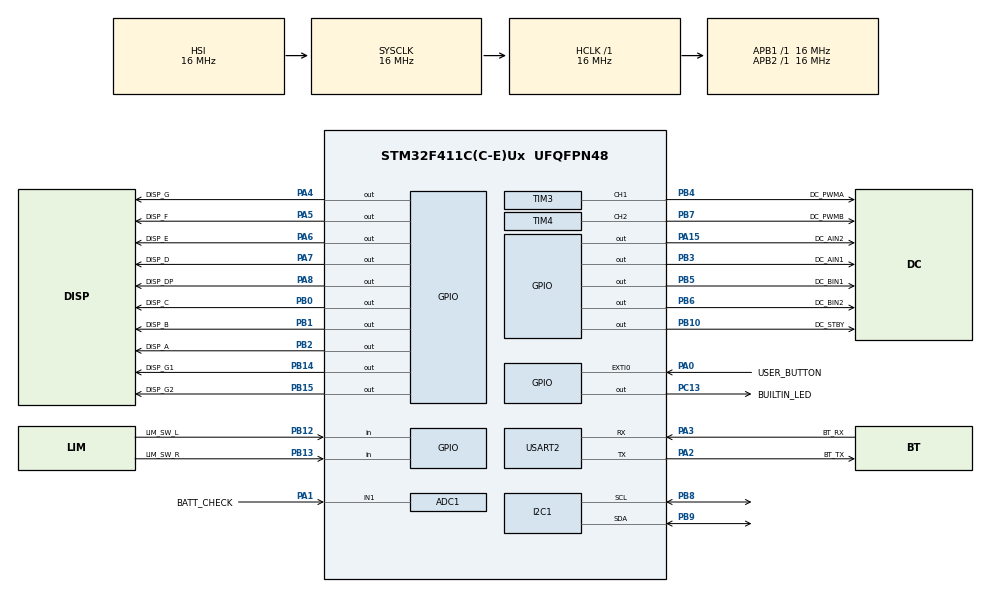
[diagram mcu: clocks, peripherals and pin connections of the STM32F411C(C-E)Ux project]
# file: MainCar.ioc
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ADC1.Channel-0\#ChannelRegularConversion=ADC_CHANNEL_1
ADC1.NbrOfConversionFlag=1
ADC1.Rank-0\#ChannelRegularConversion=1
ADC1.SamplingTime-0\#ChannelRegularConversion=ADC_SAMPLETIME_3CYCLES
ADC1.master=1
FREERTOS.Queues01=btTx,64,uint16_t,0,Dynamic,NULL,NULL;btRx,64,uint16_t,0,Dynamic,NULL,NULL
FREERTOS.Tasks01=defaultTask,24,128,startDefaultTask,Default,NULL,Dynamic,NULL,NULL;displayTask,9,1024,startDisplayTask,Default,NULL,Dynamic,NULL,NULL;driveTask,9,2048,startDriveTask,Default,NULL,Dynamic,NULL,NULL;btTask,8,2048,startBtTask,Default,NULL,Dynamic,NULL,NULL
Mcu.Family=STM32F4
Mcu.Name=STM32F411C(C-E)Ux
Mcu.Package=UFQFPN48
NVIC.PriorityGroup=NVIC_PRIORITYGROUP_4
PA0-WKUP.GPIO_Label=USER_BUTTON
PA0-WKUP.GPIO_PuPd=GPIO_PULLUP
PA0-WKUP.Signal=GPXTI0
PA1.GPIO_Label=BATT_CHECK
PA1.Signal=SharedAnalog_PA1
PA10.Signal=USART1_RX
PA15.GPIO_Label=DC_AIN2
PA15.Signal=GPIO_Output
PA2.GPIO_Label=BT_TX
PA2.Mode=Asynchronous
PA2.Signal=USART2_TX
PA3.GPIO_Label=BT_RX
PA3.Mode=Asynchronous
PA3.Signal=USART2_RX
PA4.GPIO_Label=DISP_G
PA4.Signal=GPIO_Output
PA5.GPIO_Label=DISP_F
PA5.Signal=GPIO_Output
PA6.GPIO_Label=DISP_E
PA6.Signal=GPIO_Output
PA7.GPIO_Label=DISP_D
PA7.Signal=GPIO_Output
PA8.GPIO_Label=DISP_DP
PA8.Signal=GPIO_Output
PA9.Signal=USART1_TX
PB0.GPIO_Label=DISP_C
PB0.Signal=GPIO_Output
PB1.GPIO_Label=DISP_B
PB1.Signal=GPIO_Output
PB10.GPIO_Label=DC_STBY
PB10.Signal=GPIO_Output
PB12.GPIO_Label=LIM_SW_L
PB12.GPIO_PuPd=GPIO_PULLUP
PB12.Signal=GPIO_Input
PB13.GPIO_Label=LIM_SW_R
PB13.GPIO_PuPd=GPIO_PULLUP
PB13.Signal=GPIO_Input
PB14.GPIO_Label=DISP_G1
PB14.Signal=GPIO_Output
PB15.GPIO_Label=DISP_G2
PB15.Signal=GPIO_Output
PB2.GPIO_Label=DISP_A
PB2.Signal=GPIO_Output
PB3.GPIO_Label=DC_AIN1
PB3.Signal=GPIO_Output
PB4.GPIO_Label=DC_PWMA
PB4.Signal=S_TIM3_CH1
PB5.GPIO_Label=DC_BIN1
PB5.Signal=GPIO_Output
PB6.GPIO_Label=DC_BIN2
PB6.Signal=GPIO_Output
PB7.GPIO_Label=DC_PWMB
PB7.Signal=S_TIM4_CH2
PB8.GPIO_Pu=GPIO_PULLUP
PB8.Mode=I2C
PB8.Signal=I2C1_SCL
PB9.GPIO_Pu=GPIO_PULLUP
PB9.Mode=I2C
PB9.Signal=I2C1_SDA
PC13-ANTI_TAMP.GPIO_Label=BUILTIN_LED
PC13-ANTI_TAMP.GPIO_PuPd=GPIO_NOPULL
PC13-ANTI_TAMP.Signal=GPIO_Output
ProjectManager.HeapSize=0x200
ProjectManager.StackSize=0x400
ProjectManager.TargetToolchain=STM32CubeIDE
RCC.AHBFreq_Value=16000000
RCC.APB1Freq_Value=16000000
RCC.APB2Freq_Value=16000000
RCC.CortexFreq_Value=16000000
RCC.HSE_VALUE=25000000
RCC.HSI_VALUE=16000000
RCC.LSE_VALUE=32768
RCC.SYSCLKFreq_VALUE=16000000
RCC.VCOOutputFreq_Value=192000000
SH.S_TIM3_CH1.0=TIM3_CH1,PWM Generation1 CH1
SH.S_TIM4_CH2.0=TIM4_CH2,PWM Generation2 CH2
SH.SharedAnalog_PA1.0=GPIO_Analog
SH.SharedAnalog_PA1.1=ADC1_IN1,IN1
TIM3.Channel-PWM\ Generation1\ CH1=TIM_CHANNEL_1
TIM4.Channel-PWM\ Generation2\ CH2=TIM_CHANNEL_2
USART2.VirtualMode=VM_ASYNC
VP_FREERTOS_VS_CMSIS_V2.Mode=CMSIS_V2
VP_TIM3_VS_ClockSourceINT.Mode=Internal
board=custom

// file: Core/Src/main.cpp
/* USER CODE BEGIN Header */
/**
  ******************************************************************************
  * @file           : main.c
  * @brief          : Main program body
  ******************************************************************************
  * @attention
  *
  * <h2><center>&copy; Copyright (c) 2022 STMicroelectronics.
  * All rights reserved.</center></h2>
  *
  * This software component is licensed by ST under Ultimate Liberty license
  * SLA0044, the "License"; You may not use this file except in compliance with
  * the License. You may obtain a copy of the License at:
  *                             www.st.com/SLA0044
  *
  ******************************************************************************
  */
/* USER CODE END Header */
#include <main.hh>
#include "cmsis_os.h"
#include "adc.h"
#include "i2c.h"
#include "tim.h"
#include "usart.h"
#include "gpio.h"

/* USER CODE BEGIN Includes */
#include "DigitalPin.hh"
#include "SevenSegmentX2.hh"
#include "SingleDCMotor.hh"
/* USER CODE END Includes */

void SystemClock_Config(void);
void MX_FREERTOS_Init(void);

/* USER CODE BEGIN 0 */
volatile bool run;
/* USER CODE END 0 */

int main(void)
{

  /* MCU Configuration--------------------------------------------------------*/

  /* Reset of all peripherals, Initializes the Flash interface and the Systick. */
  HAL_Init();

  /* Configure the system clock */
  SystemClock_Config();

  /* Initialize all configured peripherals */
  MX_GPIO_Init();
  MX_ADC1_Init();
  MX_I2C1_Init();
  MX_TIM3_Init();
  MX_TIM4_Init();
  MX_USART2_UART_Init();
  /* USER CODE BEGIN 2 */
  HAL_NVIC_EnableIRQ(EXTI0_IRQn);
  /* USER CODE END 2 */

  /* Init scheduler */
  osKernelInitialize();  /* Call init function for freertos objects (in freertos.c) */
  MX_FREERTOS_Init();
  /* Start scheduler */
  osKernelStart();

  /* We should never get here as control is now taken by the scheduler */
  /* Infinite loop */
  while (1)
  {

  }
}

void SystemClock_Config(void)
{
  RCC_OscInitTypeDef RCC_OscInitStruct = {0};
  RCC_ClkInitTypeDef RCC_ClkInitStruct = {0};

  /** Configure the main internal regulator output voltage
  */
  __HAL_RCC_PWR_CLK_ENABLE();
  __HAL_PWR_VOLTAGESCALING_CONFIG(PWR_REGULATOR_VOLTAGE_SCALE1);
  /** Initializes the RCC Oscillators according to the specified parameters
  * in the RCC_OscInitTypeDef structure.
  */
  RCC_OscInitStruct.OscillatorType = RCC_OSCILLATORTYPE_HSI;
  RCC_OscInitStruct.HSIState = RCC_HSI_ON;
  RCC_OscInitStruct.HSICalibrationValue = RCC_HSICALIBRATION_DEFAULT;
  RCC_OscInitStruct.PLL.PLLState = RCC_PLL_NONE;
  if (HAL_RCC_OscConfig(&RCC_OscInitStruct) != HAL_OK)
  {
    Error_Handler();
  }
  /** Initializes the CPU, AHB and APB buses clocks
  */
  RCC_ClkInitStruct.ClockType = RCC_CLOCKTYPE_HCLK|RCC_CLOCKTYPE_SYSCLK
                              |RCC_CLOCKTYPE_PCLK1|RCC_CLOCKTYPE_PCLK2;
  RCC_ClkInitStruct.SYSCLKSource = RCC_SYSCLKSOURCE_HSI;
  RCC_ClkInitStruct.AHBCLKDivider = RCC_SYSCLK_DIV1;
  RCC_ClkInitStruct.APB1CLKDivider = RCC_HCLK_DIV1;
  RCC_ClkInitStruct.APB2CLKDivider = RCC_HCLK_DIV1;

  if (HAL_RCC_ClockConfig(&RCC_ClkInitStruct, FLASH_LATENCY_0) != HAL_OK)
  {
    Error_Handler();
  }
}

void Error_Handler(void)
{
  __disable_irq();
  while (1)
  {
  }
}

/************************ (C) COPYRIGHT STMicroelectronics *****END OF FILE****/
